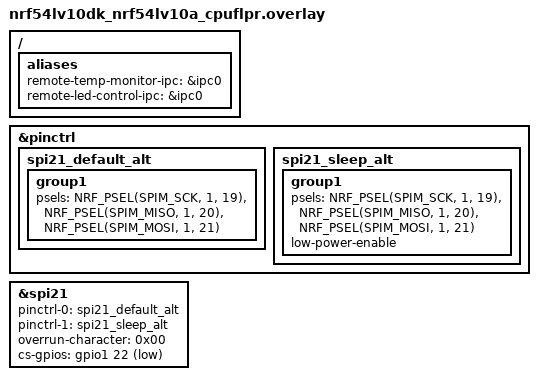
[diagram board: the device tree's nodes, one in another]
/*
 * Copyright (c) 2026 Nordic Semiconductor ASA
 *
 * SPDX-License-Identifier: LicenseRef-Nordic-5-Clause
 */

/ {
	aliases {
		remote-temp-monitor-ipc = &ipc0;
		remote-led-control-ipc = &ipc0;
	};
};

&pinctrl {
	spi21_default_alt: spi21_default_alt {
		group1 {
			psels = <NRF_PSEL(SPIM_SCK, 1, 19)>,
				<NRF_PSEL(SPIM_MISO, 1, 20)>,
				<NRF_PSEL(SPIM_MOSI, 1, 21)>;
		};
	};

	spi21_sleep_alt: spi21_sleep_alt {
		group1 {
			psels = <NRF_PSEL(SPIM_SCK, 1, 19)>,
				<NRF_PSEL(SPIM_MISO, 1, 20)>,
				<NRF_PSEL(SPIM_MOSI, 1, 21)>;
			low-power-enable;
		};
	};
};

app_spi: &spi21 {
	status = "okay";
	pinctrl-0 = <&spi21_default_alt>;
	pinctrl-1 = <&spi21_sleep_alt>;
	pinctrl-names = "default", "sleep";
	overrun-character = <0x00>;
	cs-gpios = <&gpio1 22 GPIO_ACTIVE_LOW>;
};
